# PIC16LF1764 register map
Vendor: Microchip
Registers are 8-bit, read-write, reset 0x0 unless marked. A register's access mark holds for its fields unless they carry their own. Addresses are absolute, and some are shared; only a register's first bit layout is shown; [hi:lo] are bit positions; {n}, {i} and the like mark numbered series.

## ccp
0x291 CCPR1L reset not defined — (power-on value xxxxxxxx)
  [7:0] RL
0x292 CCPR1H reset not defined — (power-on value xxxxxxxx)
  [7:0] RH
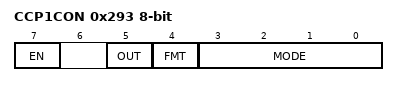
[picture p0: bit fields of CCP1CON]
0x293 CCP1CON
  [7] EN, [5] OUT ro, [4] FMT, [3:0] MODE
0x294 CCP1CAP
  [2:0] CTS

## txm_mod
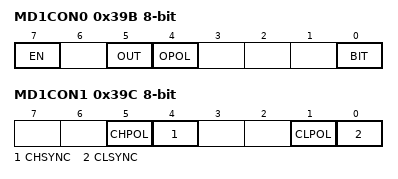
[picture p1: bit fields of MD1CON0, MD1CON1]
0x39B MD1CON0
  [7] EN, [5] OUT ro, [4] OPOL, [0] BIT
0x39C MD1CON1
  [5] CHPOL, [4] CHSYNC, [1] CLPOL, [0] CLSYNC
0x39D MD1SRC
  [4:0] MS
0x39E MD1CARL
  [3:0] CL
0x39F MD1CARH
  [3:0] CH

## amp_opamp_hvpump
0x50F OPA1NCHS
  [3:0] NCH
0x510 OPA1PCHS
  [3:0] PCH
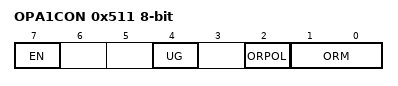
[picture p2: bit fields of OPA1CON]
0x511 OPA1CON
  [7] EN, [4] UG, [2] ORPOL, [1:0] ORM
0x512 OPA1ORS
  [4:0] ORS

## dac_nbit__ctrl
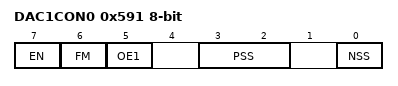
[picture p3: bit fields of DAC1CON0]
0x591 DAC1CON0
  [7] EN, [6] FM, [5] OE1, [3:2] PSS, [0] NSS
0x592 DAC1REFL
  [7:0] REF
0x593 DAC1REFH
  [7:0] REF

## 5bit_DAC_wNSS
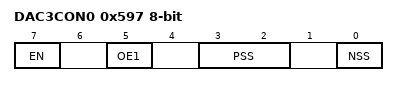
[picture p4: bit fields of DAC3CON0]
0x597 DAC3CON0
  [7] EN, [5] OE1, [3:2] PSS, [0] NSS
0x598 DAC3REF
  [4:0] DACR

## pwm
0x617 PWM3DCL reset not defined — (power-on value xx------)
  [7:6] DC
0x618 PWM3DCH reset not defined — (power-on value xxxxxxxx)
  [7:0] DC
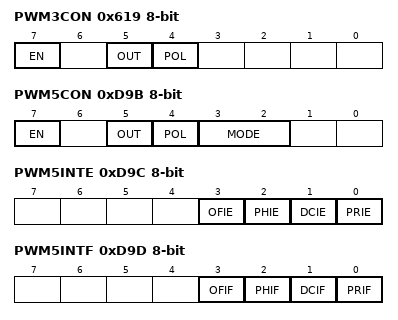
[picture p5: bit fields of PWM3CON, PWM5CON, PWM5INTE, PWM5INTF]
0x619 PWM3CON
  [7] EN, [5] OUT ro, [4] POL
0xD91 PWM5PHL reset not defined — 8-bit period timer (power-on value xxxxxxxx)
  [7:0] PH
0xD92 PWM5PHH reset not defined — (power-on value xxxxxxxx)
  [7:0] PH
0xD93 PWM5DCL reset not defined — (power-on value xxxxxxxx)
  [7:0] DC
0xD94 PWM5DCH reset not defined — (power-on value xxxxxxxx)
  [7:0] DC
0xD95 PWM5PRL reset not defined — (power-on value xxxxxxxx)
  [7:0] PR
0xD96 PWM5PRH reset not defined — (power-on value xxxxxxxx)
  [7:0] PR
0xD97 PWM5OFL reset not defined — (power-on value xxxxxxxx)
  [7:0] OF
0xD98 PWM5OFH reset not defined — (power-on value xxxxxxxx)
  [7:0] OF
0xD99 PWM5TMRL
  [7:0] TMR
0xD9A PWM5TMRH
  [7:0] TMR
0xD9B PWM5CON
  [7] EN, [5] OUT ro, [4] POL, [3:2] MODE
0xD9C PWM5INTE
  [3] OFIE, [2] PHIE, [1] DCIE, [0] PRIE
0xD9D PWM5INTF
  [3] OFIF — (can only be cleared)
  [2] PHIF — (can only be cleared)
  [1] DCIF — (can only be cleared)
  [0] PRIF — (can only be cleared)
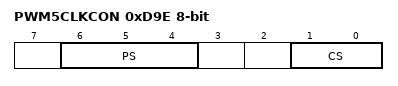
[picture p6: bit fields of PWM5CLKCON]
0xD9E PWM5CLKCON
  [6:4] PS, [1:0] CS
0xD9F PWM5LDCON
  [7] LDA
0xDA0 PWM5OFCON
  [4] OFO

## pwm_cog
0x68D COG1PHR
  [5:0] PHR
0x68E COG1PHF
  [5:0] PHF
0x68F COG1BLKR
  [5:0] BLKR
0x690 COG1BLKF
  [5:0] BLKF
0x691 COG1DBR
  [5:0] DBR
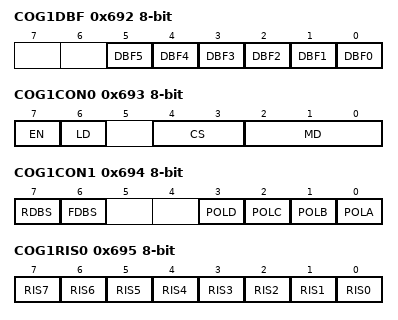
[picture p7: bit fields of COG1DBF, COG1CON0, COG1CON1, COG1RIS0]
0x692 COG1DBF
  [n] DBF{n} (n=0..5)
0x693 COG1CON0
  [7] EN, [6] LD, [4:3] CS, [2:0] MD
0x694 COG1CON1
  [7] RDBS, [6] FDBS, [3] POLD, [2] POLC, [1] POLB, [0] POLA
0x695 COG1RIS0
  [n] RIS{n} (n=0..7)
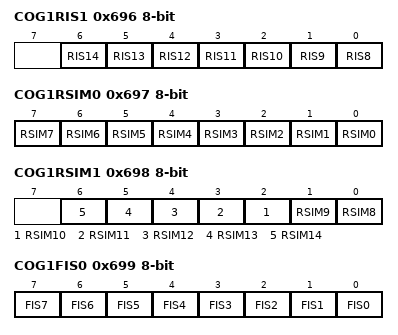
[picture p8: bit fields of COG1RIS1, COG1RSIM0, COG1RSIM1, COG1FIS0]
0x696 COG1RIS1
  [n-8] RIS{n} (n=8..14)
0x697 COG1RSIM0
  [n] RSIM{n} (n=0..7)
0x698 COG1RSIM1
  [n-8] RSIM{n} (n=8..14)
0x699 COG1FIS0
  [n] FIS{n} (n=0..7)
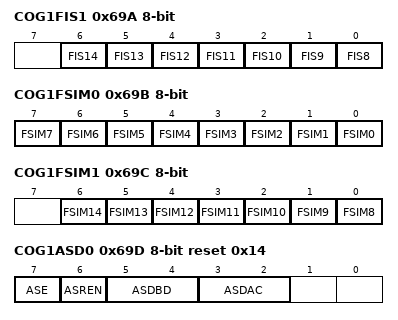
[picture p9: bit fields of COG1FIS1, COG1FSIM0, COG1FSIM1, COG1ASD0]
0x69A COG1FIS1
  [n-8] FIS{n} (n=8..14)
0x69B COG1FSIM0
  [n] FSIM{n} (n=0..7)
0x69C COG1FSIM1
  [n-8] FSIM{n} (n=8..14)
0x69D COG1ASD0 reset 0x14
  [7] ASE, [6] ASREN, [5:4] ASDBD, [3:2] ASDAC
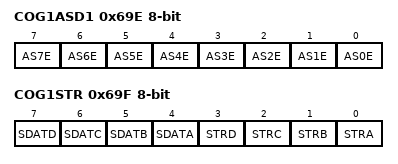
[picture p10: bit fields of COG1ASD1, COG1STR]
0x69E COG1ASD1
  [n] AS{n}E (n=0..7)
0x69F COG1STR
  [7] SDATD, [6] SDATC, [5] SDATB, [4] SDATA, [3] STRD, [2] STRC, [1] STRB, [0] STRA

## amp_sloperamp_ctrl
0x794 PRG1RTSS
  [3:0] RTSS
0x795 PRG1FTSS
  [3:0] FTSS
0x796 PRG1INS
  [3:0] INS
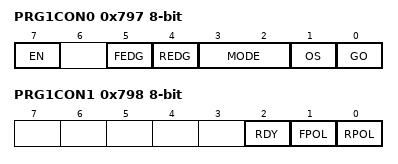
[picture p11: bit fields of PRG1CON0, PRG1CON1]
0x797 PRG1CON0
  [7] EN, [5] FEDG, [4] REDG, [3:2] MODE, [1] OS, [0] GO
0x798 PRG1CON1
  [2] RDY ro, [1] FPOL, [0] RPOL
0x799 PRG1CON2
  [4:0] ISET

## CLC
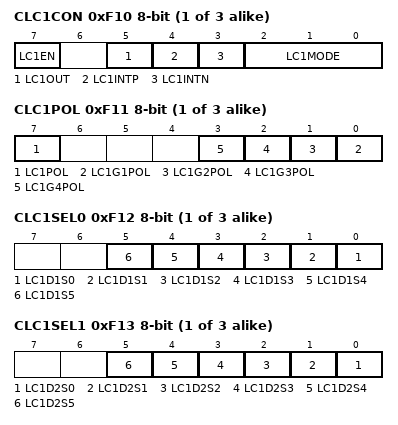
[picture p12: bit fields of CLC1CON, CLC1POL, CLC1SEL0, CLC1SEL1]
{0xF06+0xA*i} CLC{i}CON (i=1..3) — Configurable logic cell control
  [7] LC{i}EN, [5] LC{i}OUT ro, [4] LC{i}INTP, [3] LC{i}INTN, [2:0] LC{i}MODE
{0xF07+0xA*i} CLC{i}POL reset not defined (i=1..3) — Polarity control (power-on value 0---xxxx)
  [7] LC{i}POL, [n-1] LC{i}G{n}POL (n=1..4)
{0xF08+0xA*i} CLC{i}SEL0 reset not defined (i=1..3) — Input select register 1 (power-on value --xxxxxx)
  [n] LC{i}D1S{n} (n=0..5)
{0xF09+0xA*i} CLC{i}SEL1 reset not defined (i=1..3) — Input select register 1 (power-on value --xxxxxx)
  [n] LC{i}D2S{n} (n=0..5)
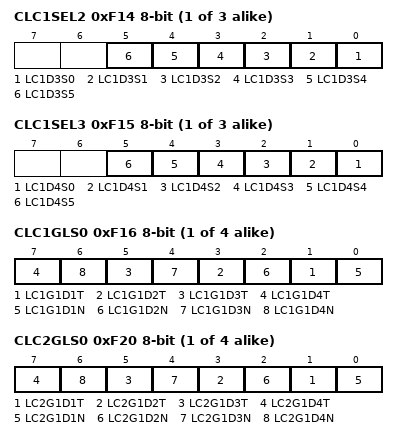
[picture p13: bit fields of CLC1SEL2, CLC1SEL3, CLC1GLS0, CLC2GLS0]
{0xF0A+0xA*i} CLC{i}SEL2 reset not defined (i=1..3) — Input select register 2 (power-on value --xxxxxx)
  [n] LC{i}D3S{n} (n=0..5)
{0xF0B+0xA*i} CLC{i}SEL3 reset not defined (i=1..3) — Input select register 3 (power-on value --xxxxxx)
  [n] LC{i}D4S{n} (n=0..5)
{0xF16+i} CLC1GLS{i} reset not defined (i=0..3) — Gate logic select register {i} (power-on value xxxxxxxx)
  [2n-1] LC1G{i+1}D{n}T (n=1..4), [2n-2] LC1G{i+1}D{n}N (n=1..4)
{0xF20+i} CLC2GLS{i} reset not defined (i=0..3) — Gate logic select register {i} (power-on value xxxxxxxx)
  [2n-1] LC2G{i+1}D{n}T (n=1..4), [2n-2] LC2G{i+1}D{n}N (n=1..4)
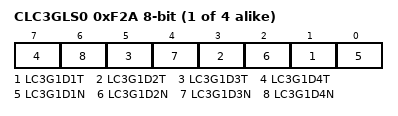
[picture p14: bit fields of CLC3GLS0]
{0xF2A+i} CLC3GLS{i} reset not defined (i=0..3) — Gate logic select register {i} (power-on value xxxxxxxx)
  [2n-1] LC3G{i+1}D{n}T (n=1..4), [2n-2] LC3G{i+1}D{n}N (n=1..4)
